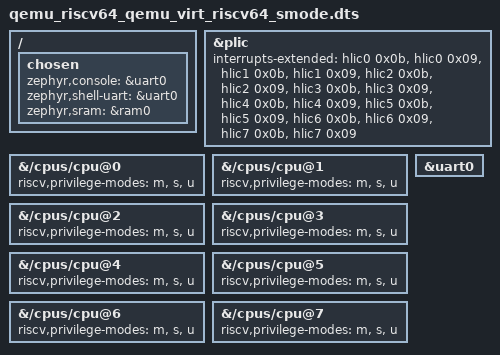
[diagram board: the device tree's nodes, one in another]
/* Copyright (c) 2026 Alexios Lyrakis */
/* SPDX-License-Identifier: Apache-2.0 */

/dts-v1/;

#include <qemu/virt-riscv64.dtsi>
#include <qemu/virt-riscv-plic.dtsi>

/*
 * With S-mode enabled QEMU lays the PLIC contexts out in M/S pairs
 * per hart (hart-config "MS,MS,...").
 */
&plic {
	interrupts-extended = <&hlic0 0x0b &hlic0 0x09
			       &hlic1 0x0b &hlic1 0x09
			       &hlic2 0x0b &hlic2 0x09
			       &hlic3 0x0b &hlic3 0x09
			       &hlic4 0x0b &hlic4 0x09
			       &hlic5 0x0b &hlic5 0x09
			       &hlic6 0x0b &hlic6 0x09
			       &hlic7 0x0b &hlic7 0x09>;
};

/ {
	chosen {
		zephyr,console = &uart0;
		zephyr,shell-uart = &uart0;
		zephyr,sram = &ram0;
	};
};

&{/cpus/cpu@0} {
	riscv,privilege-modes = "m", "s", "u";
};

&{/cpus/cpu@1} {
	riscv,privilege-modes = "m", "s", "u";
};

&{/cpus/cpu@2} {
	riscv,privilege-modes = "m", "s", "u";
};

&{/cpus/cpu@3} {
	riscv,privilege-modes = "m", "s", "u";
};

&{/cpus/cpu@4} {
	riscv,privilege-modes = "m", "s", "u";
};

&{/cpus/cpu@5} {
	riscv,privilege-modes = "m", "s", "u";
};

&{/cpus/cpu@6} {
	riscv,privilege-modes = "m", "s", "u";
};

&{/cpus/cpu@7} {
	riscv,privilege-modes = "m", "s", "u";
};

&uart0 {
	status = "okay";
};
